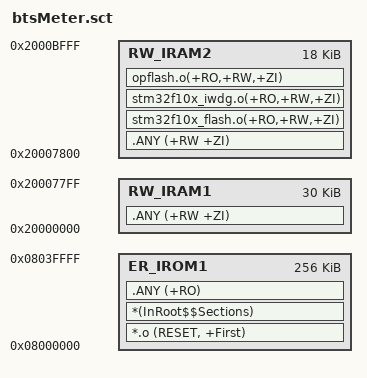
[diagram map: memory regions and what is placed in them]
; *************************************************************
; *** Scatter-Loading Description File generated by uVision ***
; *************************************************************

LR_IROM1 0x08000000 0x00040000  {    ; load region size_region
  ER_IROM1 0x08000000 0x00040000  {  ; load address = execution address
   *.o (RESET, +First)
   *(InRoot$$Sections)
   .ANY (+RO)
  }
  RW_IRAM1 0x20000000 0x00007800  {  ; RW data		   0x0000C000
   .ANY (+RW +ZI)
  ; stm32f10x_flash.o(+RO,+RW,+ZI)
  ; stm32f10x_iwdg.o(+RO,+RW,+ZI)
  ; opflash.o(+RO,+RW,+ZI)
  ; usart.o(+RO,+RW,+ZI)
  ; main.o(+RO,+RW,+ZI)
  ; stm32f10x_it.o(+RO,+RW,+ZI)
  ; stm32f10x_usart.o(+RO,+RW,+ZI)	    
  ; stm32f10x_rcc.o(+RO,+RW,+ZI)
  ; sys.o(+RO,+RW,+ZI)
  }
  RW_IRAM2 0x20007800 0x00004800  {  ; RW data
   .ANY (+RW +ZI)
    stm32f10x_flash.o(+RO,+RW,+ZI)
   stm32f10x_iwdg.o(+RO,+RW,+ZI)
   opflash.o(+RO,+RW,+ZI)
  ; usart.o(+RO,+RW,+ZI)
  ; main.o(+RO,+RW,+ZI)
  ; stm32f10x_it.o(+RO,+RW,+ZI)
  ; stm32f10x_usart.o(+RO,+RW,+ZI)	    
  ; stm32f10x_rcc.o(+RO,+RW,+ZI)
  ; sys.o(+RO,+RW,+ZI)
  }
}

